AUTOSAR XML (schema 00050)
standard types defined: Boolean, Float
package /ARRoot
  elements trigger-interface=trigger:
    sender receiver interface MotorActuatorSRIF: data-elements=variable-data-prototype=type=Boolean
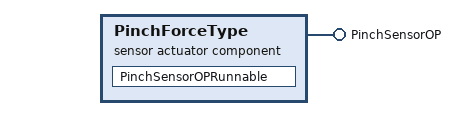
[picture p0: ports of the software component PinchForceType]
    sensor actuator sw component type PinchForceType
      provide port PinchSensorOP
      behavior PinchSensorIB
        runnable PinchSensorOPRunnable: external-triggering-point=PinchSensorOP.
    client server interface PositionSensingElementCSIF: client-server-operation=arguments=argument-data-prototype={type=Float, direction=OUT}
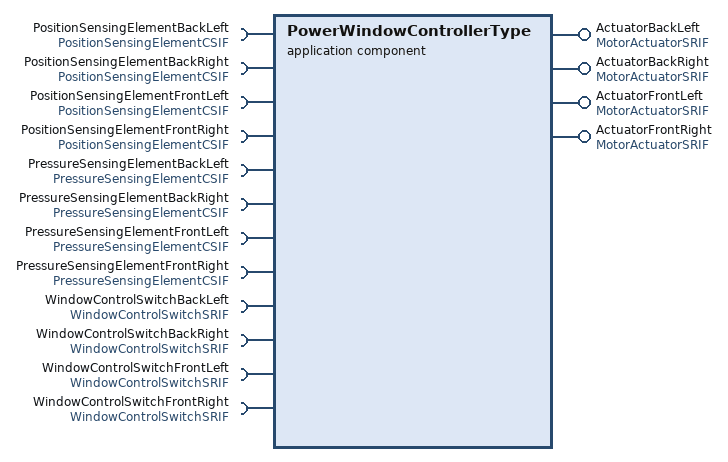
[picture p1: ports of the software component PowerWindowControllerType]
    application sw component type PowerWindowControllerType
      4 x provide port, all with provided-interface=MotorActuatorSRIF:
        ActuatorBackLeft
        ActuatorBackRight
        ActuatorFrontLeft
        ActuatorFrontRight
      12 x require port:
        PositionSensingElementBackLeft: required-interface=PositionSensingElementCSIF
        PositionSensingElementBackRight: required-interface=PositionSensingElementCSIF
        PositionSensingElementFrontLeft: required-interface=PositionSensingElementCSIF
        PositionSensingElementFrontRight: required-interface=PositionSensingElementCSIF
        PressureSensingElementBackLeft: required-interface=PressureSensingElementCSIF
        PressureSensingElementBackRight: required-interface=PressureSensingElementCSIF
        PressureSensingElementFrontLeft: required-interface=PressureSensingElementCSIF
        PressureSensingElementFrontRight: required-interface=PressureSensingElementCSIF
        WindowControlSwitchBackLeft: required-interface=WindowControlSwitchSRIF
        WindowControlSwitchBackRight: required-interface=WindowControlSwitchSRIF
        WindowControlSwitchFrontLeft: required-interface=WindowControlSwitchSRIF
        WindowControlSwitchFrontRight: required-interface=WindowControlSwitchSRIF
      behavior PowerWindowIB
        16 x runnable:
          ActuatorBackLeftRunnable: variable-access=accessed-variable=/ARRoot/MotorActuatorSRIF/
          ActuatorBackRightRunnable: variable-access=accessed-variable=/ARRoot/MotorActuatorSRIF/
          ActuatorFrontLeftRunnable: variable-access=accessed-variable=/ARRoot/MotorActuatorSRIF/
          ActuatorFrontRightRunnable: variable-access=accessed-variable=/ARRoot/MotorActuatorSRIF/
          PositionSensingElementBackLeftRunnable: synchronous-server-call-point=PositionSensingElementBackLeft.
          PositionSensingElementBackRightRunnable: synchronous-server-call-point=PositionSensingElementBackRight.
          PositionSensingElementFrontLeftRunnable: synchronous-server-call-point=PositionSensingElementFrontLeft.
          PositionSensingElementFrontRightRunnable: synchronous-server-call-point=PositionSensingElementFrontRight.
          PressureSensingElementBackLeftRunnable: synchronous-server-call-point=PressureSensingElementBackLeft.
          PressureSensingElementBackRightRunnable: synchronous-server-call-point=PressureSensingElementBackRight.
          PressureSensingElementFrontLeftRunnable: synchronous-server-call-point=PressureSensingElementFrontLeft.
          PressureSensingElementFrontRightRunnable: synchronous-server-call-point=WindowControlSwitchFrontRight.
          WindowControlSwitchBackLeftRunnable: variable-access=accessed-variable=/ARRoot/WindowControlSwitchSRIF/
          WindowControlSwitchBackRightRunnable: variable-access=accessed-variable=/ARRoot/WindowControlSwitchSRIF/
          WindowControlSwitchFrontLeftRunnable: variable-access=accessed-variable=/ARRoot/WindowControlSwitchSRIF/
          WindowControlSwitchFrontRightRunnable: variable-access=accessed-variable=/ARRoot/WindowControlSwitchSRIF/
    client server interface PressureSensingElementCSIF
    sender receiver interface WindowControlSwitchSRIF: data-elements=variable-data-prototype=type=Boolean
